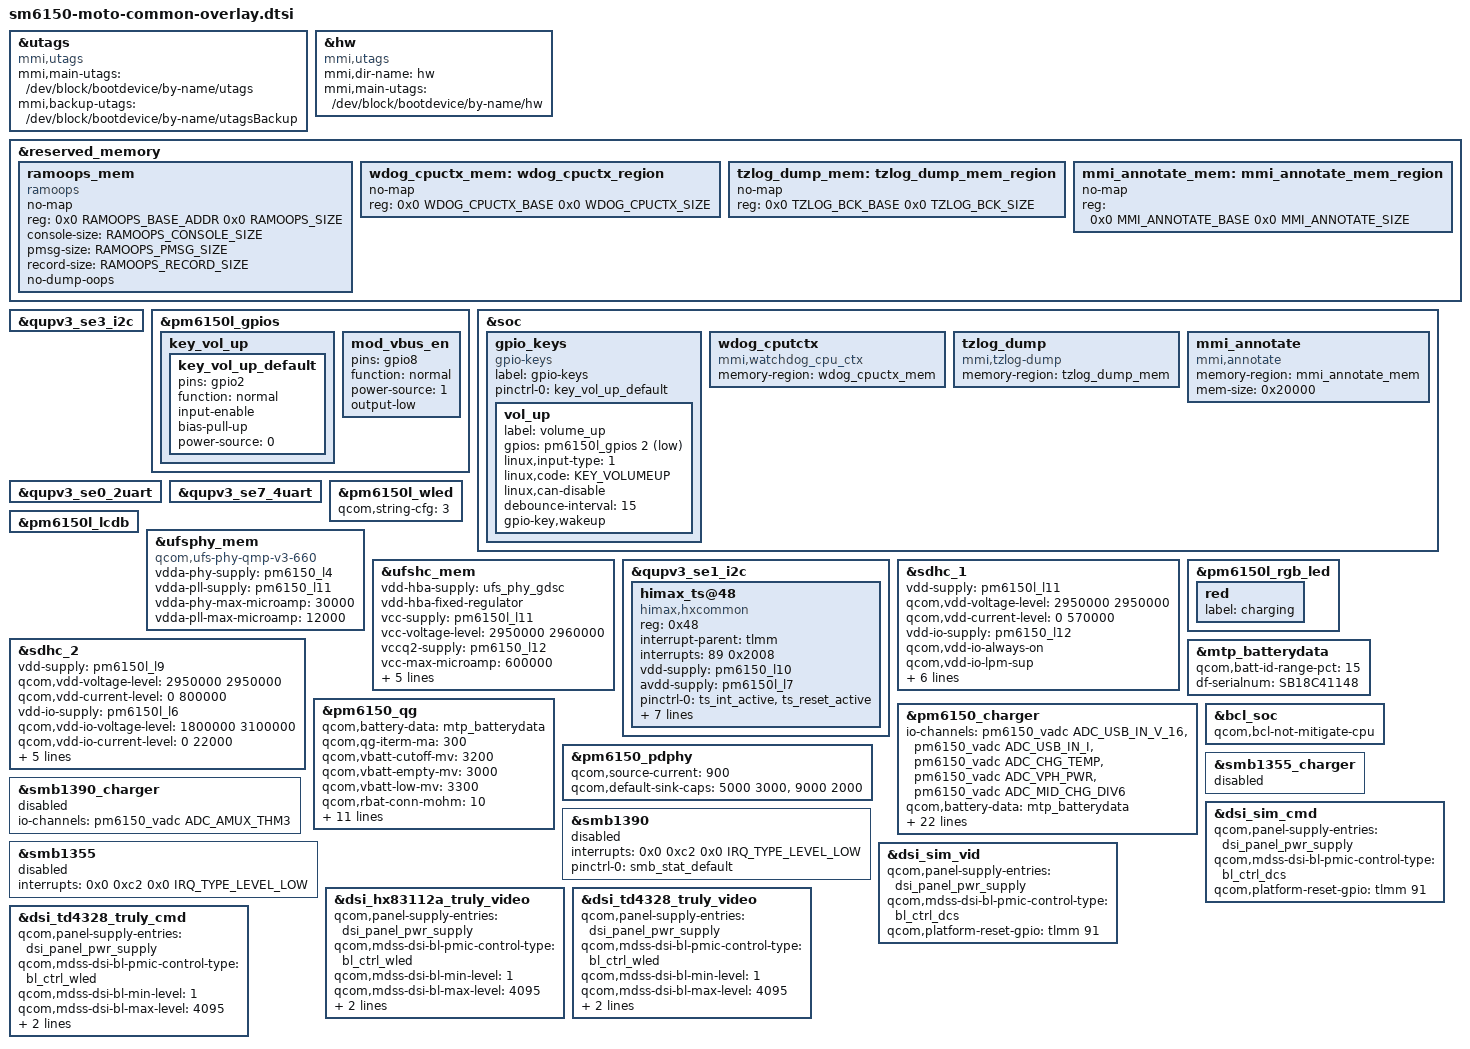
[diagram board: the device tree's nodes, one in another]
/* Copyright (c) 2018, The Linux Foundation. All rights reserved.
 *
 * This program is free software; you can redistribute it and/or modify
 * it under the terms of the GNU General Public License version 2 and
 * only version 2 as published by the Free Software Foundation.
 *
 * This program is distributed in the hope that it will be useful,
 * but WITHOUT ANY WARRANTY; without even the implied warranty of
 * MERCHANTABILITY or FITNESS FOR A PARTICULAR PURPOSE.  See the
 * GNU General Public License for more details.
 */

#include "carrier-channel-ids.dtsi"
#include "sm6150-thermal-overlay.dtsi"
#include "sm6150-camera-sensor-mot-foles-overlay.dtsi"
#include <dt-bindings/gpio/gpio.h>
#include <dt-bindings/iio/qcom,spmi-vadc.h>
#include <dt-bindings/input/input.h>
#include "sm6150-sde-display.dtsi"
#include "dsi-panel-mot-dummy-qhd-video.dtsi"
#include <dt-bindings/moto/moto-mem-reserve.h>

&utags {
	compatible = "mmi,utags";
	mmi,main-utags = "/dev/block/bootdevice/by-name/utags";
	mmi,backup-utags = "/dev/block/bootdevice/by-name/utagsBackup";
};

&hw {
	compatible = "mmi,utags";
	mmi,dir-name = "hw";
	mmi,main-utags = "/dev/block/bootdevice/by-name/hw";
};

&reserved_memory {
	ramoops_mem {
		compatible = "ramoops";
		no-map;
		reg = <0x0 RAMOOPS_BASE_ADDR 0x0 RAMOOPS_SIZE>;
		console-size = <RAMOOPS_CONSOLE_SIZE>;
		pmsg-size = <RAMOOPS_PMSG_SIZE>;
		record-size = <RAMOOPS_RECORD_SIZE>;
		no-dump-oops;
	};

	wdog_cpuctx_mem: wdog_cpuctx_region {
		no-map;
		reg = <0x0 WDOG_CPUCTX_BASE
				0x0 WDOG_CPUCTX_SIZE>;
	};

	tzlog_dump_mem: tzlog_dump_mem_region {
		no-map;
		reg = <0x0  TZLOG_BCK_BASE
				0x0 TZLOG_BCK_SIZE>;
	};

	mmi_annotate_mem: mmi_annotate_mem_region {
		no-map;
		reg = <0x0  MMI_ANNOTATE_BASE
				0x0 MMI_ANNOTATE_SIZE>;
	};
};

&qupv3_se3_i2c {
	status = "ok";
	#include "smb1390.dtsi"
	#include "smb1355.dtsi"
};

&pm6150l_gpios {
	key_vol_up {
		key_vol_up_default: key_vol_up_default {
			pins = "gpio2";
			function = "normal";
			input-enable;
			bias-pull-up;
			power-source = <0>;
		};
	};

	mod_vbus_en: mod_vbus_en {
		pins = "gpio8";
		function = "normal";
		power-source = <1>;
		output-low;
	};
};

&soc {
	gpio_keys {
		compatible = "gpio-keys";
		label = "gpio-keys";

		pinctrl-names = "default";
		pinctrl-0 = <&key_vol_up_default>;

		vol_up {
			label = "volume_up";
			gpios = <&pm6150l_gpios 2 GPIO_ACTIVE_LOW>;
			linux,input-type = <1>;
			linux,code = <KEY_VOLUMEUP>;
			linux,can-disable;
			debounce-interval = <15>;
			gpio-key,wakeup;
		};
	};

	wdog_cputctx {
		compatible = "mmi,watchdog_cpu_ctx";
		memory-region = <&wdog_cpuctx_mem>;
	};

	tzlog_dump {
		compatible = "mmi,tzlog-dump";
		memory-region = <&tzlog_dump_mem>;
	};

	mmi_annotate {
		compatible = "mmi,annotate";
		memory-region = <&mmi_annotate_mem>;
		mem-size = <0x20000>;
	};
};

&qupv3_se0_2uart {
	status = "ok";
};

&qupv3_se7_4uart {
	status = "ok";
};

&pm6150l_wled {
	qcom,string-cfg= <3>;
	status = "ok";
};

&pm6150l_lcdb {
	status = "ok";
};

&ufsphy_mem {
	compatible = "qcom,ufs-phy-qmp-v3-660";

	vdda-phy-supply = <&pm6150_l4>; /* 0.9v */
	vdda-pll-supply = <&pm6150_l11>;
	vdda-phy-max-microamp = <30000>;
	vdda-pll-max-microamp = <12000>;

	status = "ok";
};

&ufshc_mem {
	vdd-hba-supply = <&ufs_phy_gdsc>;
	vdd-hba-fixed-regulator;
	vcc-supply = <&pm6150l_l11>;
	vcc-voltage-level = <2950000 2960000>;
	vccq2-supply = <&pm6150_l12>;
	vcc-max-microamp = <600000>;
	vccq2-max-microamp = <600000>;

	qcom,vddp-ref-clk-supply = <&pm6150l_l3>;
	qcom,vddp-ref-clk-max-microamp = <100>;
	qcom,vddp-ref-clk-min-uV = <1232000>;
	qcom,vddp-ref-clk-max-uV = <1260000>;

	status = "ok";
};

&qupv3_se1_i2c {
	status = "okay";
	himax_ts@48 {
		compatible = "himax,hxcommon";
		reg = <0x48>;
		interrupt-parent = <&tlmm>;
		interrupts = <89 0x2008>;
		vdd-supply = <&pm6150_l10>;
		avdd-supply = <&pm6150l_l7>;
		pinctrl-names = "pmx_ts_active","pmx_ts_suspend",
					"pmx_ts_release";
		pinctrl-0 = <&ts_int_active &ts_reset_active>;
		pinctrl-1 = <&ts_int_suspend &ts_reset_suspend>;
		pinctrl-2 = <&ts_release>;
		himax,panel-coords = <0 1080 0 2160>;
		himax,display-coords = <0 1080 0 2160>;
		himax,irq-gpio = <&tlmm 89 0x00>;
		himax,rst-gpio = <&tlmm 88 0x00>;
		report_type = <1>;
	};
};

&sdhc_1 {
	vdd-supply = <&pm6150l_l11>;
	qcom,vdd-voltage-level = <2950000 2950000>;
	qcom,vdd-current-level = <0 570000>;

	vdd-io-supply = <&pm6150_l12>;
	qcom,vdd-io-always-on;
	qcom,vdd-io-lpm-sup;
	qcom,vdd-io-voltage-level = <1800000 1800000>;
	qcom,vdd-io-current-level = <0 325000>;

	pinctrl-names = "active", "sleep";
	pinctrl-0 = <&sdc1_clk_on &sdc1_cmd_on &sdc1_data_on &sdc1_rclk_on>;
	pinctrl-1 = <&sdc1_clk_off &sdc1_cmd_off &sdc1_data_off &sdc1_rclk_off>;

	status = "ok";
};

&sdhc_2 {
	vdd-supply = <&pm6150l_l9>;
	qcom,vdd-voltage-level = <2950000 2950000>;
	qcom,vdd-current-level = <0 800000>;

	vdd-io-supply = <&pm6150l_l6>;
	qcom,vdd-io-voltage-level = <1800000 3100000>;
	qcom,vdd-io-current-level = <0 22000>;

	pinctrl-names = "active", "sleep";
	pinctrl-0 = <&sdc2_clk_on  &sdc2_cmd_on &sdc2_data_on &sdc2_cd_on>;
	pinctrl-1 = <&sdc2_clk_off &sdc2_cmd_off &sdc2_data_off &sdc2_cd_off>;

	cd-gpios = <&tlmm 99 1>;

	status = "ok";
};

&pm6150l_rgb_led {
	red {
		label = "charging";
	};
};

&mtp_batterydata {
	qcom,batt-id-range-pct = <15>;
	df-serialnum = "SB18C41148";
	#include "qg-batterydata-kz40-atl-3600mah.dtsi"
	#include "qg-batterydata-kz40-swd-3600mah.dtsi"
};

&pm6150_qg {
	qcom,battery-data = <&mtp_batterydata>;
	qcom,qg-iterm-ma = <300>;
	qcom,vbatt-cutoff-mv = <3200>;
	qcom,vbatt-empty-mv = <3000>;
	qcom,vbatt-low-mv = <3300>;
	qcom,rbat-conn-mohm = <10>;
	qcom,cl-feedback-on;
	qcom,cl-min-start-soc = <0>;
	qcom,cl-max-start-soc = <5>;
	qcom,cl-min-temp = <150>;
	qcom,cl-max-temp = <450>;
	qcom,cl-max-increment = <5>;
	qcom,cl-max-decrement = <10>;
	qcom,cl-min-limit = <200>;
	qcom,cl-max-limit = <30>;
	qcom,s3-entry-ibat-ua = <15000>;
	qcom,s3-exit-ibat-ua = <35000>;
};

&pm6150_charger {
	io-channels = <&pm6150_vadc ADC_USB_IN_V_16>,
		      <&pm6150_vadc ADC_USB_IN_I>,
		      <&pm6150_vadc ADC_CHG_TEMP>,
		      <&pm6150_vadc ADC_VPH_PWR>,
		      <&pm6150_vadc ADC_MID_CHG_DIV6>;
	io-channel-names = "usb_in_voltage",
			   "usb_in_current",
			   "chg_temp",
			   "vph_voltage",
			   "dcin_v";
	qcom,battery-data = <&mtp_batterydata>;
	qcom,iterm-ma = <175>;
	qcom,fcc-max-ua = <3600000>;
	qcom,fv-max-uv = <4400000>;
	qcom,usb-icl-ua = <3000000>;
	qcom,dc-icl-ua = <1500000>;
	qcom,eb-batt-psy-name = "gb_battery";
	qcom,eb-pwr-psy-name = "gb_ptp";
	qcom,dc-eb-icl-ma = <900>;
	qcom,dc-eb-icl-eff-ma = <500>;
	qcom,thermal-mitigation = <3600>,
				   <3000>,
				   <2500>,
				   <2000>,
				   <1500>,
				   <1200>,
				   <900>,
				   <700>,
				   <300>;
	qcom,mmi-temp-zones = <0 4200 700 0>,
				<10 4200 1750 700>,
				<15 0 1750 1750>,
				<45 4200 3600 2500>,
				<60 4200 1750 0>;
	qcom,enable-charging-limit;
	qcom,upper-limit-capacity = <75>;
	qcom,lower-limit-capacity = <60>;
	qcom,usbpd-phandle = <&pm6150_pdphy>;
	qcom,disable-suspend-on-collapse;
	qcom,support-mods;
};

&pm6150_pdphy {
	qcom,source-current = <900>;
	qcom,default-sink-caps = <5000 3000>, /* 5V @ 3A */
				 <9000 2000>; /* 9V @ 2A */
};

&pm6150_charger {
	gpios = <&pm6150l_gpios 8 0x0>; /* GPIOF_OUT_INIT_LOW */
	gpio-names = "eb_vbus_en";
};

&bcl_soc {
	qcom,bcl-not-mitigate-cpu;
};

&smb1390 {
	/delete-property/ interrupts;
	interrupts = <0x0 0xc2 0x0 IRQ_TYPE_LEVEL_LOW>;
	pinctrl-names = "default";
	pinctrl-0 = <&smb_stat_default>;
	status = "disabled";
};

&smb1390_charger {
	io-channels = <&pm6150_vadc ADC_AMUX_THM3>;
	io-channel-names = "cp_die_temp";
	status = "disabled";
};

&smb1355 {
	/delete-property/ interrupts;
	interrupts = <0x0 0xc2 0x0 IRQ_TYPE_LEVEL_LOW>;
	status = "disabled";
};

&smb1355_charger {
	status = "disabled";
};

&dsi_sim_cmd {
	qcom,panel-supply-entries = <&dsi_panel_pwr_supply>;
	qcom,mdss-dsi-bl-pmic-control-type = "bl_ctrl_dcs";
	qcom,platform-reset-gpio = <&tlmm 91 0>;
};

&dsi_sim_vid {
	qcom,panel-supply-entries = <&dsi_panel_pwr_supply>;
	qcom,mdss-dsi-bl-pmic-control-type = "bl_ctrl_dcs";
	qcom,platform-reset-gpio = <&tlmm 91 0>;
};

&dsi_hx83112a_truly_video {
	qcom,panel-supply-entries = <&dsi_panel_pwr_supply>;
	qcom,mdss-dsi-bl-pmic-control-type = "bl_ctrl_wled";
	qcom,mdss-dsi-bl-min-level = <1>;
	qcom,mdss-dsi-bl-max-level = <4095>;
	qcom,platform-te-gpio = <&tlmm 90 0>;
	qcom,platform-reset-gpio = <&tlmm 91 0>;
};

&dsi_td4328_truly_video {
	qcom,panel-supply-entries = <&dsi_panel_pwr_supply>;
	qcom,mdss-dsi-bl-pmic-control-type = "bl_ctrl_wled";
	qcom,mdss-dsi-bl-min-level = <1>;
	qcom,mdss-dsi-bl-max-level = <4095>;
	qcom,platform-te-gpio = <&tlmm 90 0>;
	qcom,platform-reset-gpio = <&tlmm 91 0>;
};

&dsi_td4328_truly_cmd {
	qcom,panel-supply-entries = <&dsi_panel_pwr_supply>;
	qcom,mdss-dsi-bl-pmic-control-type = "bl_ctrl_wled";
	qcom,mdss-dsi-bl-min-level = <1>;
	qcom,mdss-dsi-bl-max-level = <4095>;
	qcom,platform-te-gpio = <&tlmm 90 0>;
	qcom,platform-reset-gpio = <&tlmm 91 0>;
};
